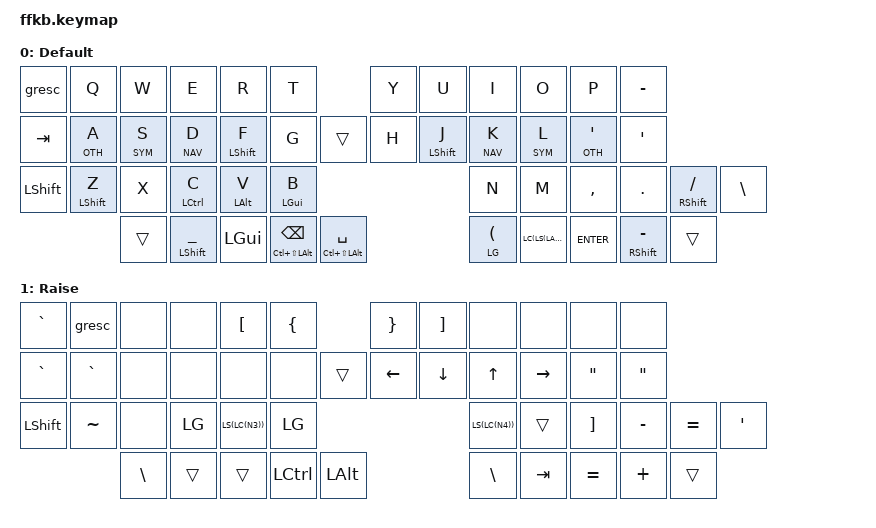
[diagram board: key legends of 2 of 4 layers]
#include <behaviors.dtsi>
#include <dt-bindings/zmk/keys.h>
#include <dt-bindings/zmk/rgb.h>
#include <dt-bindings/zmk/bt.h>
#include <dt-bindings/zmk/ext_power.h>
#include <dt-bindings/zmk/outputs.h>

#define DEFAULT 0
#define NAV     1
#define SYM     2
#define OTH     3


#define TAPPING_TERM 200
#define QUICK_TAP    200

&lt {
	flavor = "tap-preferred";
	tapping-term-ms = <TAPPING_TERM>;
    quick-tap-ms = <QUICK_TAP>;
};

&mt {
	flavor = "tap-preferred";
	tapping-term-ms = <TAPPING_TERM>;
    quick-tap-ms = <QUICK_TAP>;
};
&caps_word {
    continue-list = <UNDERSCORE MINUS>;
};

/ {
    combos {
        compatible = "zmk,combos";
        combo_undo {
            timeout-ms = <50>;
            key-positions = <26 27>;
            bindings = <&kp LC(Z)>;
        };

        combo_q {
            timeout-ms = <50>;
            key-positions = <27 28>;
            bindings = <&kp Q>;
        };
        combo_semicolon {
            timeout-ms = <50>;
            key-positions = <33 34>;
            bindings = <&kp SEMI>;
        };
    };
};

/ {

    sensors {
        compatible = "zmk,keymap-sensors";
        sensors = <&encoder_1 &encoder_2>;
    };

    behaviors {
        tdclr: tap_dance_0 {
            compatible = "zmk,behavior-tap-dance";
            label = "TAP_DANCE_0";
            #binding-cells = <0>;
            tapping-term-ms = <200>;
            bindings = <&none>, <&bt BT_CLR>;
        };
        tdrst: tap_dance_1 {
            compatible = "zmk,behavior-tap-dance";
            label = "TAP_DANCE_0";
            #binding-cells = <0>;
            tapping-term-ms = <200>;
            bindings = <&none>, <&bootloader>;
        };
        hm: layer_mods {
            compatible = "tap-preferred";
            label = "LAYER_MODS";
            #binding-cells = <2>;
            tapping-term-ms = <200>;
            quick_tap_ms = <0>;
            flavor = "balanced";
            bindings = <&kp>, <&kp>;
        };
        hs: homerow_shift {
            compatible = "zmk,behavior-hold-tap";
            label = "HOMEROW_SHIFT";
            #binding-cells = <2>;
            tapping-term-ms = <175>;
            quick_tap_ms = <0>;
            flavor = "tap-preferred";
            bindings = <&kp>, <&kp>;
        };
        tdg: tap_dance_g {
            compatible = "zmk,behavior-tap-dance";
            label = "TAP_DANCE_G";
            #binding-cells = <0>;
            tapping-term-ms = <QUICK_TAP>;
            bindings = <&kp G>, <&caps_word>;
        };
        tdh: tap_dance_h {
            compatible = "zmk,behavior-tap-dance";
            label = "TAP_DANCE_M";
            #binding-cells = <0>;
            tapping-term-ms = <QUICK_TAP>;
            bindings = <&kp H>, <&caps_word>;
        };
        rgb_encoder: rgb_encoder {
            compatible = "zmk,behavior-sensor-rotate";
            label = "RGB_ENCODER";
            #sensor-binding-cells = <0>;
            bindings = <&rgb_ug RGB_BRD>, <&rgb_ug RGB_BRI>;
        };
    };

    keymap {
        compatible = "zmk,keymap";

        default_layer {
            label = "Default";

            sensor-bindings = <&rgb_encoder &rgb_encoder &rgb_encoder >;

            bindings = <
    &gresc     &kp Q         &kp W        &kp E       &kp R         &kp T                              &kp Y        &kp U          &kp I       &kp O         &kp P         &kp MINUS
    &kp TAB    &lt OTH A     &lt SYM S    &lt NAV D   &hs LSHIFT F  &kp G                &trans        &kp H        &hs LSHIFT J   &lt NAV K   &lt SYM L     &lt OTH SQT  &kp SINGLE_QUOTE
    &kp LSHIFT &mt LSHIFT Z  &kp X        &mt LCTL C       &mt LALT V         &mt LGUI B                              &kp N        &kp M          &kp COMMA   &kp DOT       &mt RSHFT FSLH      &kp BSLH
                            &trans       &mt LSHFT UNDER  &kp LGUI  &mt LC(LS(LALT)) BSPC                      &mt LC(LS(LALT)) SPACE &mt LG(LC(LS(LALT))) ENTER  &mt RSHFT MINUS &trans
            >;
        };

        raise_layer {
            label = "Raise";

            sensor-bindings = <&inc_dec_kp C_VOLUME_UP C_VOLUME_DOWN &inc_dec_kp LG(EQUAL) LG(MINUS) &inc_dec_kp LG(EQUAL) LG(MINUS)>;

            bindings = <
    &kp GRAVE   &gresc        &none       &none      &kp LBKT   &kp LBRC                                  &kp RBRC   &kp RBKT        &none       &none      &none      &none
    &kp GRAVE    &kp GRAVE    &none       &none      &none       &none                &trans              &kp LEFT  &kp DOWN    &kp UP      &kp RIGHT  &kp DQT    &kp DQT
    &kp LSHIFT &kp TILDE  &none        &kp LG(LS(LC(N3))) &kp LG(LS(LC(N4)))         &trans                             &kp RBKT  &kp MINUS   &kp EQUAL   &kp SQT    &kp BSLH   &trans
                                        &trans      &kp LCTL  &kp LALT   &kp BSLH                         &kp TAB  &kp EQUAL   &kp PLUS      &trans
            >;
        };
        lower_layer {
            label = "Lower  ";

            sensor-bindings = <&inc_dec_kp C_VOLUME_UP C_VOLUME_DOWN &inc_dec_kp C_VOLUME_UP C_VOLUME_DOWN &inc_dec_kp C_VOLUME_UP C_VOLUME_DOWN>;

            bindings = <
    &kp TILDE   &kp N1     &kp N2     &kp N3     &kp N4     &kp N5                    &kp N6 &kp N7     &kp N8     &kp N9     &kp N0    &kp EQUAL
    &kp TILDE   &rgb_ug RGB_TOG &rgb_ug RGB_EFR &rgb_ug RGB_HUI &rgb_ug RGB_BRI   &trans           &kp LEFT  &kp DOWN    &kp UP      &kp RIGHT  &kp SEMI    &kp SEMI 
    &kp LSHIFT  &rgb_ug RGB_TOG &rgb_ug RGB_EFF &rgb_ug RGB_HUD &rgb_ug RGB_BRD    &trans                               &rgb_ug RGB_TOG &rgb_ug RGB_EFR  &rgb_ug RGB_EFF &rgb_ug RGB_BRI &kp SEMI     &trans
                                        &trans      &trans        &kp LALT      &kp BSPC        &kp LC(LEFT)   &kp LC(UP)    &kp LC(RIGHT)      &trans
            >;
        };
    util_layer {
            label = "Util";

            sensor-bindings = <&inc_dec_kp C_VOLUME_UP C_VOLUME_DOWN &inc_dec_kp C_VOLUME_UP C_VOLUME_DOWN &inc_dec_kp C_VOLUME_UP C_VOLUME_DOWN>;

            bindings = <
    &kp GRAVE  &kp EXCL &kp AT &kp HASH  &kp DOLLAR &kp PRCNT                                      &kp CARET &kp AMPS  &kp KP_MULTIPLY &kp LPAR  &kp RPAR    &kp EQUAL
    &trans     &tdclr    &bt BT_SEL 0 &bt BT_SEL 1 &bt BT_SEL 2 &bt BT_SEL 3               &trans           &kp LEFT        &kp DOWN         &kp UP        &kp RIGHT   &kp COLON    &trans
    &kp LSHIFT &trans   &trans       &trans      &trans       &tdrst                                &tdrst &rgb_ug RGB_EFR  &rgb_ug RGB_EFF &rgb_ug RGB_BRI &rgb_ug RGB_BRD     &trans
                                        &trans      &trans        &kp LALT      &kp BSPC        &kp LC(LEFT)   &kp LC(UP)    &kp LC(RIGHT)      &trans
            >;
        };
    };
};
